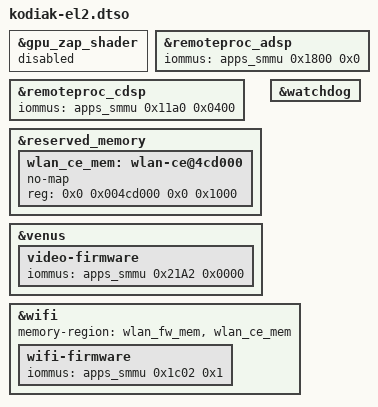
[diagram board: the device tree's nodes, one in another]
// SPDX-License-Identifier: BSD-3-Clause
/*
 * Copyright (c) Qualcomm Technologies, Inc. and/or its subsidiaries.
 *
 * Kodiak specific modifications required to boot in EL2.
 */

/dts-v1/;
/plugin/;

&gpu_zap_shader {
	status = "disabled";
};

&remoteproc_adsp {
	iommus = <&apps_smmu 0x1800 0x0>;
};

&remoteproc_cdsp {
	iommus = <&apps_smmu 0x11a0 0x0400>;
};

&reserved_memory {
	#address-cells = <2>;
	#size-cells = <2>;

	wlan_ce_mem: wlan-ce@4cd000 {
		no-map;
		reg = <0x0 0x004cd000 0x0 0x1000>;
	};
};

&venus {
	status = "okay";
	video-firmware {
		iommus = <&apps_smmu 0x21A2 0x0000>;
	};
};

&watchdog {
	status = "okay";
};

&wifi {
	memory-region = <&wlan_fw_mem>, <&wlan_ce_mem>;
	status = "okay";

	wifi-firmware {
		iommus = <&apps_smmu 0x1c02 0x1>;
	};
};
